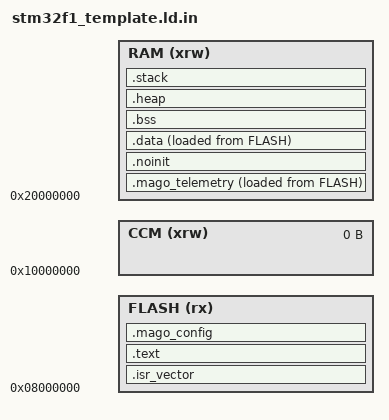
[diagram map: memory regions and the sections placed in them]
/**
 * @file stm32f1_template.ld.in
 * @brief Mago41 - Linker Script Template
 *
 * Processed by CMake to substitute @FLASH_SIZE@ and @RAM_SIZE@
 *
 * Diferencia radical vs RS41HUP_V2:
 * - Memory layout explícito para sections custom
 * - .mago_config section for config storage
 * - .mago_telemetry section for telemetry buffers
 * - .noinit section for persistent data across resets
 */

MEMORY
{
    FLASH (rx)  : ORIGIN = 0x08000000, LENGTH = @FLASH_SIZE@
    RAM (xrw)   : ORIGIN = 0x20000000, LENGTH = @RAM_SIZE@
    CCM (xrw)   : ORIGIN = 0x10000000, LENGTH = 0K  /* Not on F100/F103 */
}

/* Stack/Heap configuration */
_estack = ORIGIN(RAM) + LENGTH(RAM);
_Min_Heap_Size = 0;
_Min_Stack_Size = 2K;

/* ============================================================================
 * SECTIONS
 * ============================================================================ */

SECTIONS
{
    /* ================================================================
     * INTERRUPT VECTOR TABLE
     * ================================================================ */
    .isr_vector :
    {
        . = ALIGN(4);
        KEEP(*(.isr_vector))
        . = ALIGN(4);
    } >FLASH

    /* ================================================================
     * TEXT (CODE + RO DATA)
     * ================================================================ */
    .text :
    {
        . = ALIGN(4);
        *(.text*)
        *(.rodata*)
        *(.glue_7)
        *(.glue_7t)
        *(.eh_frame*)
        . = ALIGN(4);
    } >FLASH

    /* ================================================================
     * MAGO41 CONFIG STORAGE (last page of flash)
     * ================================================================ */
    .mago_config (NOLOAD) :
    {
        . = ALIGN(4);
        __config_start = .;
        *(.mago_config)
        __config_end = .;
        . = ALIGN(4);
    } >FLASH AT> FLASH

    /* ================================================================
     * MAGO41 TELEMETRY BUFFERS
     * ================================================================ */
    .mago_telemetry (NOLOAD) :
    {
        . = ALIGN(4);
        __telemetry_start = .;
        *(.mago_telemetry)
        __telemetry_end = .;
        . = ALIGN(4);
    } >RAM AT> FLASH

    /* ================================================================
     * PERSISTENT DATA (survives reset)
     * ================================================================ */
    .noinit (NOLOAD) :
    {
        . = ALIGN(4);
        __noinit_start = .;
        *(.noinit)
        __noinit_end = .;
        . = ALIGN(4);
    } >RAM

    /* ================================================================
     * DATA (INITIALIZED RW DATA)
     * ================================================================ */
    .data :
    {
        . = ALIGN(4);
        _sdata = .;
        *(.data*)
        . = ALIGN(4);
        _edata = .;
    } >RAM AT> FLASH

    /* ================================================================
     * BSS (ZERO-INITIALIZED DATA)
     * ================================================================ */
    .bss :
    {
        . = ALIGN(4);
        _sbss = .;
        *(.bss*)
        *(COMMON)
        . = ALIGN(4);
        _ebss = .;
    } >RAM

    /* ================================================================
     * HEAP
     * ================================================================ */
    .heap (NOLOAD) :
    {
        . = ALIGN(8);
        __heap_start = .;
        . += _Min_Heap_Size;
        __heap_end = .;
    } >RAM

    /* ================================================================
     * STACK
     * ================================================================ */
    .stack (NOLOAD) :
    {
        . = ALIGN(8);
        __stack_end = .;
        . += _Min_Stack_Size;
        __stack_start = .;
    } >RAM

    /* ================================================================
     * DEBUG INFO
     * ================================================================ */
    /DISCARD/ :
    {
        *(.note.GNU-stack)
        *(.gnu_debuglink)
        *(.gnu.lto_*)
    }
}

/* ============================================================================
 * SYMBOLS FOR APPLICATION
 * ============================================================================ */
PROVIDE(__flash_start = ORIGIN(FLASH));
PROVIDE(__flash_end = ORIGIN(FLASH) + LENGTH(FLASH));
PROVIDE(__ram_start = ORIGIN(RAM));
PROVIDE(__ram_end = ORIGIN(RAM) + LENGTH(RAM));
PROVIDE(__data_start = _sdata);
PROVIDE(__data_end = _edata);
PROVIDE(__bss_start = _sbss);
PROVIDE(__bss_end = _ebss);
PROVIDE(__config_start = __config_start);
PROVIDE(__config_end = __config_end);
